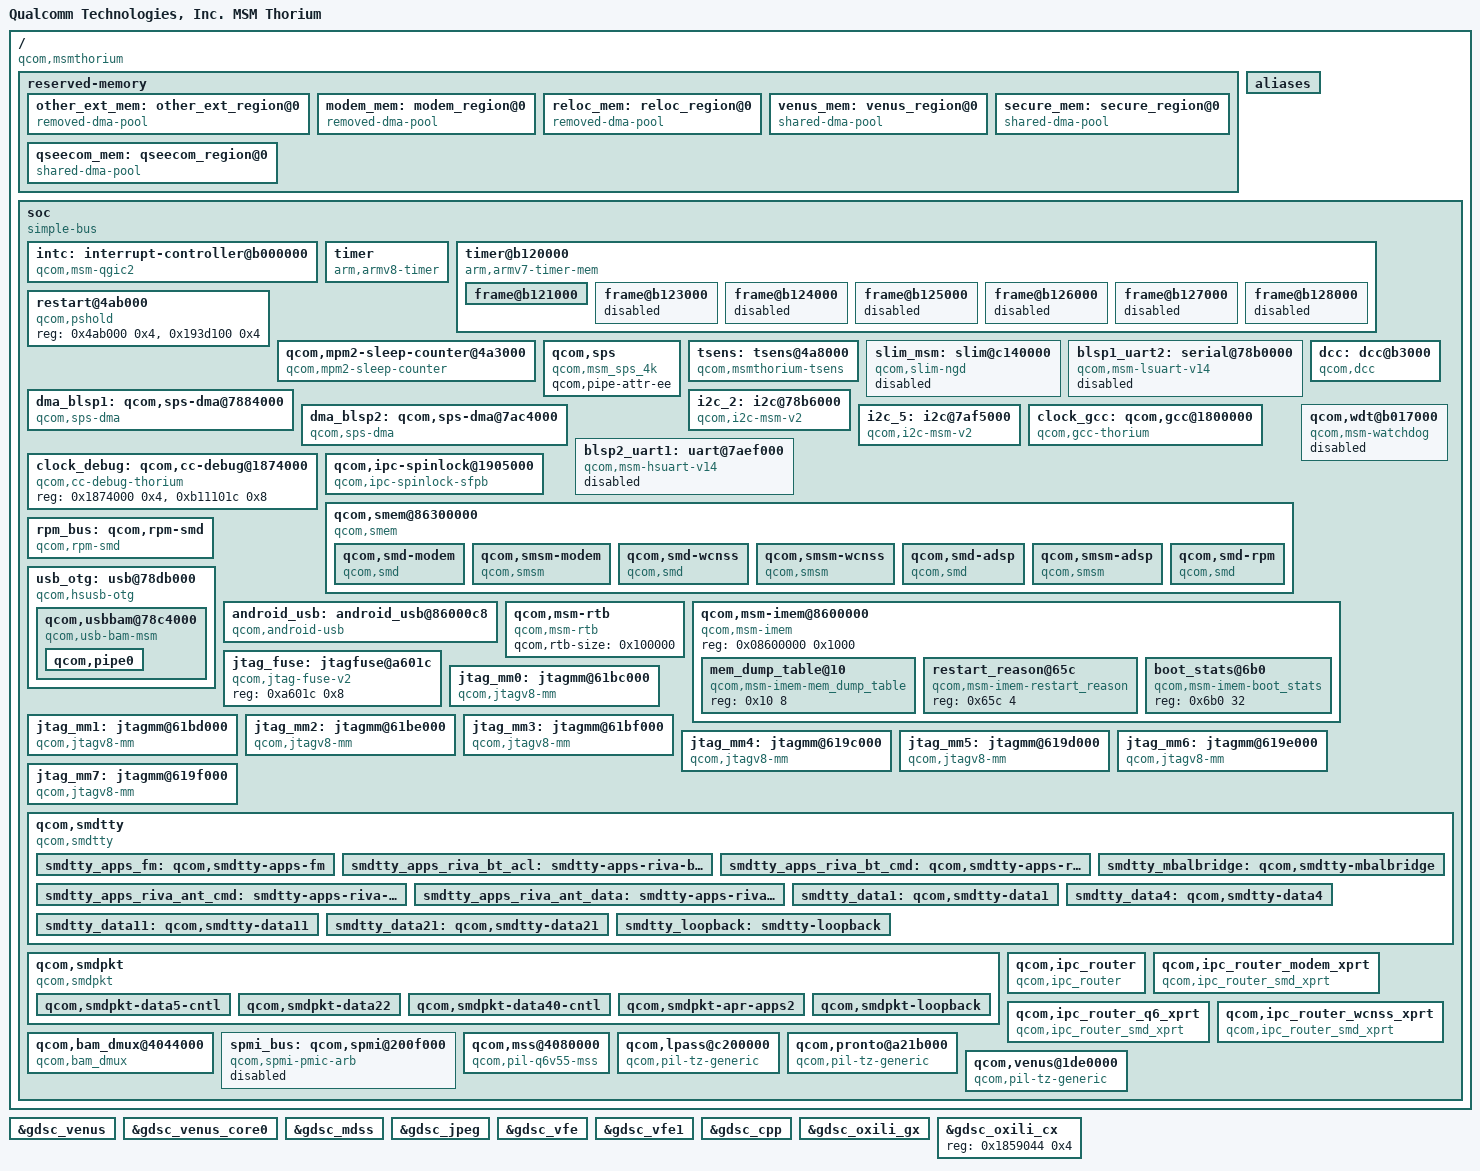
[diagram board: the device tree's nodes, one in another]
/*
 * Copyright (c) 2015, The Linux Foundation. All rights reserved.
 *
 * This program is free software; you can redistribute it and/or modify
 * it under the terms of the GNU General Public License version 2 and
 * only version 2 as published by the Free Software Foundation.
 *
 * This program is distributed in the hope that it will be useful,
 * but WITHOUT ANY WARRANTY; without even the implied warranty of
 * MERCHANTABILITY or FITNESS FOR A PARTICULAR PURPOSE.  See the
 * GNU General Public License for more details.
 */

#include "skeleton64.dtsi"
#include <dt-bindings/clock/msm-clocks-8952.h>
#include <dt-bindings/regulator/qcom,rpm-smd-regulator.h>

/ {
	model = "Qualcomm Technologies, Inc. MSM Thorium";
	compatible = "qcom,msmthorium";
	qcom,msm-id = <294 0x0>;
	interrupt-parent = <&intc>;

	reserved-memory {
		#address-cells = <2>;
		#size-cells = <2>;
		ranges;

		other_ext_mem: other_ext_region@0 {
			compatible = "removed-dma-pool";
			no-map;
			reg = <0x0 0x85e00000 0x0 0xa00000>;
		};

		modem_mem: modem_region@0 {
			compatible = "removed-dma-pool";
			no-map;
			reg = <0x0 0x86800000 0x0 0x5a00000>;
		};

		reloc_mem: reloc_region@0 {
			compatible = "removed-dma-pool";
			no-map;
			reg = <0x0 0x8c200000 0x0 0x1b00000>;
		};

		venus_mem: venus_region@0 {
			compatible = "shared-dma-pool";
			reusable;
			alloc-ranges = <0x0 0x80000000 0x0 0x10000000>;
			alignment = <0 0x400000>;
			size = <0 0x0800000>;
		};

		secure_mem: secure_region@0 {
			compatible = "shared-dma-pool";
			reusable;
			alignment = <0 0x400000>;
			size = <0 0x7000000>;
		};

		qseecom_mem: qseecom_region@0 {
			compatible = "shared-dma-pool";
			reusable;
			alignment = <0 0x400000>;
			size = <0 0x1000000>;
		};
	};

	aliases {
		/* smdtty devices */
		smd1 = &smdtty_apps_fm;
		smd2 = &smdtty_apps_riva_bt_acl;
		smd3 = &smdtty_apps_riva_bt_cmd;
		smd4 = &smdtty_mbalbridge;
		smd5 = &smdtty_apps_riva_ant_cmd;
		smd6 = &smdtty_apps_riva_ant_data;
		smd7 = &smdtty_data1;
		smd8 = &smdtty_data4;
		smd11 = &smdtty_data11;
		smd21 = &smdtty_data21;
		smd36 = &smdtty_loopback;
		i2c2 = &i2c_2;
		i2c5 = &i2c_5;
	};

	soc: soc { };

};

#include "msmthorium-pinctrl.dtsi"
#include "msmthorium-cpu.dtsi"
#include "msmthorium-ion.dtsi"
#include "msm-arm-smmu-thorium.dtsi"
#include "msmthorium-coresight.dtsi"
#include "msmthorium-smp2p.dtsi"

&soc {
	#address-cells = <1>;
	#size-cells = <1>;
	ranges = <0 0 0 0xffffffff>;
	compatible = "simple-bus";

	intc: interrupt-controller@b000000 {
		compatible = "qcom,msm-qgic2";
		interrupt-controller;
		#interrupt-cells = <3>;
		reg = <0x0b000000 0x1000>,
		      <0x0b002000 0x1000>;
	};

	timer {
		compatible = "arm,armv8-timer";
		interrupts = <1 2 0xff08>,
			     <1 3 0xff08>,
			     <1 4 0xff08>,
			     <1 1 0xff08>;
		clock-frequency = <19200000>;
	};

	timer@b120000 {
		#address-cells = <1>;
		#size-cells = <1>;
		ranges;
		compatible = "arm,armv7-timer-mem";
		reg = <0xb120000 0x1000>;
		clock-frequency = <19200000>;

		frame@b121000 {
			frame-number = <0>;
			interrupts = <0 8 0x4>,
				     <0 7 0x4>;
			reg = <0xb121000 0x1000>,
			      <0xb122000 0x1000>;
		};

		frame@b123000 {
			frame-number = <1>;
			interrupts = <0 9 0x4>;
			reg = <0xb123000 0x1000>;
			status = "disabled";
		};

		frame@b124000 {
			frame-number = <2>;
			interrupts = <0 10 0x4>;
			reg = <0xb124000 0x1000>;
			status = "disabled";
		};

		frame@b125000 {
			frame-number = <3>;
			interrupts = <0 11 0x4>;
			reg = <0xb125000 0x1000>;
			status = "disabled";
		};

		frame@b126000 {
			frame-number = <4>;
			interrupts = <0 12 0x4>;
			reg = <0xb126000 0x1000>;
			status = "disabled";
		};

		frame@b127000 {
			frame-number = <5>;
			interrupts = <0 13 0x4>;
			reg = <0xb127000 0x1000>;
			status = "disabled";
		};

		frame@b128000 {
			frame-number = <6>;
			interrupts = <0 14 0x4>;
			reg = <0xb128000 0x1000>;
			status = "disabled";
		};
	};

	restart@4ab000 {
		compatible = "qcom,pshold";
		reg = <0x4ab000 0x4>,
			<0x193d100 0x4>;
		reg-names = "pshold-base", "tcsr-boot-misc-detect";
	};

	qcom,mpm2-sleep-counter@4a3000 {
		compatible = "qcom,mpm2-sleep-counter";
		reg = <0x4a3000 0x1000>;
		clock-frequency = <32768>;
	};

	qcom,sps {
		compatible = "qcom,msm_sps_4k";
		qcom,pipe-attr-ee;
	};

	tsens: tsens@4a8000 {
		compatible = "qcom,msmthorium-tsens";
		reg = <0x4a8000 0x2000>,
		      <0xa4000  0x1000>;
		reg-names = "tsens_physical", "tsens_eeprom_physical";
		interrupts = <0 184 0>;
		interrupt-names = "tsens-upper-lower";
		qcom,sensors = <11>;
		qcom,slope = <3200 3200 3200 3200 3200 3200 3200 3200 3200
								3200 3200>;
		qcom,sensor-id = <0 1 2 3 4 5 6 7 8 9 10>;
	};

	slim_msm: slim@c140000{
		cell-index = <1>;
		compatible = "qcom,slim-ngd";
		reg = <0xc140000 0x2c000>,
		      <0xc104000 0x2a000>;
		reg-names = "slimbus_physical", "slimbus_bam_physical";
		interrupts = <0 163 0>, <0 180 0>;
		interrupt-names = "slimbus_irq", "slimbus_bam_irq";
		qcom,apps-ch-pipes = <0x600000>;
		qcom,ea-pc = <0x230>;
		status = "disabled";
	};

	blsp1_uart2: serial@78b0000 {
		compatible = "qcom,msm-lsuart-v14";
		reg = <0x78b0000 0x200>;
		interrupts = <0 108 0>;
		status = "disabled";
		clocks = <&clock_gcc clk_gcc_blsp1_uart2_apps_clk>,
		<&clock_gcc clk_gcc_blsp1_ahb_clk>;
		clock-names = "core_clk", "iface_clk";
	};

	dma_blsp1: qcom,sps-dma@7884000 { /* BLSP1 */
		#dma-cells = <4>;
		compatible = "qcom,sps-dma";
		reg = <0x7884000 0x1f000>;
		interrupts = <0 238 0>;
		qcom,summing-threshold = <10>;
	};

	dma_blsp2: qcom,sps-dma@7ac4000 { /* BLSP2 */
		#dma-cells = <4>;
		compatible = "qcom,sps-dma";
		reg = <0x7ac4000 0x1f000>;
		interrupts = <0 239 0>;
		qcom,summing-threshold = <10>;
	};

	i2c_2: i2c@78b6000 { /* BLSP1 QUP2 */
		compatible = "qcom,i2c-msm-v2";
		#address-cells = <1>;
		#size-cells = <0>;
		reg-names = "qup_phys_addr";
		reg = <0x78b6000 0x600>;
		interrupt-names = "qup_irq";
		interrupts = <0 96 0>;
		qcom,clk-freq-out = <400000>;
		qcom,clk-freq-in  = <19200000>;
		clock-names = "iface_clk", "core_clk";
		clocks = <&clock_gcc clk_gcc_blsp1_ahb_clk>,
			<&clock_gcc clk_gcc_blsp1_qup2_i2c_apps_clk>;

		pinctrl-names = "i2c_active", "i2c_sleep";
		pinctrl-0 = <&i2c_2_active>;
		pinctrl-1 = <&i2c_2_sleep>;
		qcom,noise-rjct-scl = <0>;
		qcom,noise-rjct-sda = <0>;
		qcom,master-id = <86>;
		dmas = <&dma_blsp1 6 64 0x20000020 0x20>,
			<&dma_blsp1 7 32 0x20000020 0x20>;
		dma-names = "tx", "rx";
	};

	i2c_5: i2c@7af5000 { /* BLSP2 QUP1 */
		compatible = "qcom,i2c-msm-v2";
		#address-cells = <1>;
		#size-cells = <0>;
		reg-names = "qup_phys_addr";
		reg = <0x7af5000 0x600>;
		interrupt-names = "qup_irq";
		interrupts = <0 299 0>;
		qcom,clk-freq-out = <400000>;
		qcom,clk-freq-in  = <19200000>;
		clock-names = "iface_clk", "core_clk";
		clocks = <&clock_gcc clk_gcc_blsp2_ahb_clk>,
			<&clock_gcc clk_gcc_blsp2_qup1_i2c_apps_clk>;

		pinctrl-names = "i2c_active", "i2c_sleep";
		pinctrl-0 = <&i2c_5_active>;
		pinctrl-1 = <&i2c_5_sleep>;
		qcom,noise-rjct-scl = <0>;
		qcom,noise-rjct-sda = <0>;
		qcom,master-id = <84>;
		dmas = <&dma_blsp2 4 64 0x20000020 0x20>,
			<&dma_blsp2 5 32 0x20000020 0x20>;
		dma-names = "tx", "rx";
	};

	clock_gcc: qcom,gcc@1800000 {
		compatible = "qcom,gcc-thorium";
		reg = <0x1800000 0x80000>,
			<0xb116000 0x00040>,
			<0xb016000 0x00040>,
			<0xb1d0000 0x00040>;
		reg-names = "cc_base", "apcs_c0_base",
			"apcs_c1_base", "apcs_cci_base";
		vdd_dig-supply = <&pmthorium_s2_level>;
		vdd_sr2_dig-supply = <&pmthorium_s2_level_ao>;
		vdd_sr2_pll-supply = <&pmthorium_l7_ao>;
		vdd_hf_dig-supply = <&pmthorium_s2_level_ao>;
		vdd_hf_pll-supply = <&pmthorium_l7_ao>;
		#clock-cells = <1>;
	};

	clock_debug: qcom,cc-debug@1874000 {
		compatible = "qcom,cc-debug-thorium";
		reg = <0x1874000 0x4>,
		      <0xb11101c 0x8>;
		reg-names = "cc_base", "meas";
		#clock-cells = <1>;
	};

	blsp2_uart1: uart@7aef000 {
		compatible = "qcom,msm-hsuart-v14";
		reg = <0x7aef000 0x200>,
			<0x7ac4000 0x1f000>;
		reg-names = "core_mem", "bam_mem";
		interrupt-names = "core_irq", "bam_irq", "wakeup_irq";
		#address-cells = <0>;
		interrupt-parent = <&blsp2_uart1>;
		interrupts = <0 1 2>;
		#interrupt-cells = <1>;
		interrupt-map-mask = <0xffffffff>;
		interrupt-map = <0 &intc 0 306 0
				1 &intc 0 239 0
				2 &tlmm 17 0>;

		qcom,inject-rx-on-wakeup;
		qcom,rx-char-to-inject = <0xfd>;

		qcom,bam-tx-ep-pipe-index = <0>;
		qcom,bam-rx-ep-pipe-index = <1>;
		qcom,master-id = <84>;
		clock-names = "core_clk", "iface_clk";
		clocks = <&clock_gcc clk_gcc_blsp2_uart1_apps_clk>,
				<&clock_gcc clk_gcc_blsp2_ahb_clk>;
		pinctrl-names = "sleep", "default";
		pinctrl-0 = <&blsp2_uart1_sleep>;
		pinctrl-1 = <&blsp2_uart1_active>;
		qcom,msm-bus,name = "blsp2_uart1";
		qcom,msm-bus,num-cases = <2>;
		qcom,msm-bus,num-paths = <1>;
		qcom,msm-bus,vectors-KBps =
				<84 512 0 0>,
				<84 512 500 800>;
		status = "disabled";
	};

	dcc: dcc@b3000 {
		compatible = "qcom,dcc";
		reg = <0xb3000 0x1000>,
		      <0xb4000 0x2000>;
		reg-names = "dcc-base", "dcc-ram-base";

		clocks = <&clock_gcc clk_gcc_dcc_clk>;
		clock-names = "dcc_clk";

		qcom,save-reg;
	};

	qcom,ipc-spinlock@1905000 {
		compatible = "qcom,ipc-spinlock-sfpb";
		reg = <0x1905000 0x8000>;
		qcom,num-locks = <8>;
	};

	qcom,smem@86300000 {
		compatible = "qcom,smem";
		reg = <0x86300000 0x100000>,
			<0xb011008 0x4>,
			<0x60000 0x8000>,
			<0x193d000 0x8>;
		reg-names = "smem", "irq-reg-base", "aux-mem1",
				"smem_targ_info_reg";
		qcom,mpu-enabled;

		qcom,smd-modem {
			compatible = "qcom,smd";
			qcom,smd-edge = <0>;
			qcom,smd-irq-offset = <0x0>;
			qcom,smd-irq-bitmask = <0x1000>;
			interrupts = <0 25 1>;
			label = "modem";
		};

		qcom,smsm-modem {
			compatible = "qcom,smsm";
			qcom,smsm-edge = <0>;
			qcom,smsm-irq-offset = <0x0>;
			qcom,smsm-irq-bitmask = <0x2000>;
			interrupts = <0 26 1>;
		};

		qcom,smd-wcnss {
			compatible = "qcom,smd";
			qcom,smd-edge = <6>;
			qcom,smd-irq-offset = <0x0>;
			qcom,smd-irq-bitmask = <0x20000>;
			interrupts = <0 142 1>;
			label = "wcnss";
		};

		qcom,smsm-wcnss {
			compatible = "qcom,smsm";
			qcom,smsm-edge = <6>;
			qcom,smsm-irq-offset = <0x0>;
			qcom,smsm-irq-bitmask = <0x80000>;
			interrupts = <0 144 1>;
		};

		qcom,smd-adsp {
			compatible = "qcom,smd";
			qcom,smd-edge = <1>;
			qcom,smd-irq-offset = <0x0>;
			qcom,smd-irq-bitmask = <0x100>;
			interrupts = <0 289 1>;
			label = "adsp";
		};

		qcom,smsm-adsp {
			compatible = "qcom,smsm";
			qcom,smsm-edge = <1>;
			qcom,smsm-irq-offset = <0x0>;
			qcom,smsm-irq-bitmask = <0x200>;
			interrupts = <0 290 1>;
		};

		qcom,smd-rpm {
			compatible = "qcom,smd";
			qcom,smd-edge = <15>;
			qcom,smd-irq-offset = <0x0>;
			qcom,smd-irq-bitmask = <0x1>;
			interrupts = <0 168 1>;
			label = "rpm";
			qcom,irq-no-suspend;
			qcom,not-loadable;
		};
	};

	rpm_bus: qcom,rpm-smd {
		compatible = "qcom,rpm-smd";
		rpm-channel-name = "rpm_requests";
		rpm-channel-type = <15>; /* SMD_APPS_RPM */
		rpm-standalone; /* TODO: Remove once RPM communication is up */
	};

	usb_otg: usb@78db000 {
		compatible = "qcom,hsusb-otg";
		reg = <0x78db000 0x400>, <0x6c000 0x200>;
		reg-names = "core", "phy_csr";
		#address-cells = <1>;
		#size-cells = <1>;
		ranges;

		interrupts = <0 134 0>,<0 140 0>;
		interrupt-names = "core_irq", "async_irq";

		hsusb_vdd_dig-supply = <&pmthorium_l2>;
		HSUSB_1p8-supply = <&pmthorium_l7>;
		HSUSB_3p3-supply = <&pmthorium_l13>;
		vbus_otg-supply = <&smbcharger_charger_otg>;
		qcom,vdd-voltage-level = <0 1200000 1200000>;

		qcom,hsusb-otg-phy-type = <3>; /* SNPS Femto PHY */
		qcom,hsusb-otg-mode = <3>; /* OTG mode */
		qcom,hsusb-otg-otg-control = <2>; /* PMIC */
		qcom,dp-manual-pullup;
		qcom,hsusb-otg-mpm-dpsehv-int = <49>;
		qcom,hsusb-otg-mpm-dmsehv-int = <58>;
		qcom,phy-dvdd-always-on;
		qcom,boost-sysclk-with-streaming;

		qcom,msm-bus,name = "usb2";
		qcom,msm-bus,num-cases = <3>;
		qcom,msm-bus,num-paths = <1>;
		qcom,msm-bus,vectors-KBps =
				<87 512 0 0>,
				<87 512 80000 0>,
				<87 512 6000  6000>;
		clocks = <&clock_gcc clk_gcc_usb_hs_ahb_clk>,
			 <&clock_gcc clk_gcc_usb_hs_system_clk>,
			 <&clock_gcc clk_gcc_usb2a_phy_sleep_clk>,
			 <&clock_gcc clk_bimc_usb_a_clk>,
			 <&clock_gcc clk_snoc_usb_a_clk>,
			 <&clock_gcc clk_pnoc_usb_a_clk>,
			 <&clock_gcc clk_gcc_qusb2_phy_clk>,
			 <&clock_gcc clk_gcc_usb2_hs_phy_only_clk>,
			 <&clock_gcc clk_gcc_usb_hs_phy_cfg_ahb_clk>,
			 <&clock_gcc clk_xo_otg_clk>;
		clock-names = "iface_clk", "core_clk", "sleep_clk",
				"bimc_clk", "snoc_clk", "pcnoc_clk",
				"phy_reset_clk", "phy_por_clk", "phy_csr_clk",
				"xo";
		qcom,bus-clk-rate = <748800000 200000000 100000000>;
		qcom,max-nominal-sysclk-rate = <133330000>;

		qcom,usbbam@78c4000 {
			compatible = "qcom,usb-bam-msm";
			reg = <0x78c4000 0x17000>;
			interrupt-parent = <&intc>;
			interrupts = <0 135 0>;

			qcom,bam-type = <1>;
			qcom,usb-bam-num-pipes = <4>;
			qcom,usb-bam-fifo-baseaddr = <0x08605000>;
			qcom,ignore-core-reset-ack;
			qcom,disable-clk-gating;
			qcom,usb-bam-max-mbps-highspeed = <400>;
			qcom,reset-bam-on-disconnect;

			qcom,pipe0 {
				label = "hsusb-qdss-in-0";
				qcom,usb-bam-mem-type = <2>;
				qcom,dir = <1>;
				qcom,pipe-num = <0>;
				qcom,peer-bam = <0>;
				qcom,peer-bam-physical-address = <0x6044000>;
				qcom,src-bam-pipe-index = <0>;
				qcom,dst-bam-pipe-index = <0>;
				qcom,data-fifo-offset = <0x0>;
				qcom,data-fifo-size = <0xe00>;
				qcom,descriptor-fifo-offset = <0xe00>;
				qcom,descriptor-fifo-size = <0x200>;
			};
		};
	};

	android_usb: android_usb@86000c8 {
		compatible = "qcom,android-usb";
		reg = <0x086000c8 0xc8>;
		qcom,pm-qos-latency = <2 1001 12701>;
	};

	qcom,wdt@b017000 {
		compatible = "qcom,msm-watchdog";
		reg = <0xb017000 0x1000>;
		reg-names = "wdt-base";
		interrupts = <0 3 0>, <0 4 0>;
		qcom,bark-time = <11000>;
		qcom,pet-time = <10000>;
		qcom,ipi-ping;
		qcom,wakeup-enable;
		status = "disabled";
	};

	qcom,msm-rtb {
		compatible = "qcom,msm-rtb";
		qcom,rtb-size = <0x100000>; /* 1M EBI1 buffer */
	};

	qcom,msm-imem@8600000 {
		compatible = "qcom,msm-imem";
		reg = <0x08600000 0x1000>; /* Address and size of IMEM */
		ranges = <0x0 0x08600000 0x1000>;
		#address-cells = <1>;
		#size-cells = <1>;

		mem_dump_table@10 {
			compatible = "qcom,msm-imem-mem_dump_table";
			reg = <0x10 8>;
		};

		restart_reason@65c {
			compatible = "qcom,msm-imem-restart_reason";
			reg = <0x65c 4>;
		};

		boot_stats@6b0 {
			compatible = "qcom,msm-imem-boot_stats";
			reg = <0x6b0 32>;
		};
	};

	jtag_fuse: jtagfuse@a601c {
		compatible = "qcom,jtag-fuse-v2";
		reg = <0xa601c 0x8>;
		reg-names = "fuse-base";
	};

	jtag_mm0: jtagmm@61bc000 {
		compatible = "qcom,jtagv8-mm";
		reg = <0x61bc000 0x1000>,
		      <0x61b0000 0x1000>;
		reg-names = "etm-base", "debug-base";

		qcom,coresight-jtagmm-cpu = <&CPU4>;

		clocks = <&clock_gcc clk_qdss_clk>,
			 <&clock_gcc clk_qdss_a_clk>;
		clock-names = "core_clk", "core_a_clk";
	};

	jtag_mm1: jtagmm@61bd000 {
		compatible = "qcom,jtagv8-mm";
		reg = <0x61bd000 0x1000>,
		      <0x61b2000 0x1000>;
		reg-names = "etm-base", "debug-base";

		qcom,coresight-jtagmm-cpu = <&CPU5>;

		clocks = <&clock_gcc clk_qdss_clk>,
			 <&clock_gcc clk_qdss_a_clk>;
		clock-names = "core_clk", "core_a_clk";
	};

	jtag_mm2: jtagmm@61be000 {
		compatible = "qcom,jtagv8-mm";
		reg = <0x61be000 0x1000>,
		      <0x61b4000 0x1000>;
		reg-names = "etm-base", "debug-base";

		qcom,coresight-jtagmm-cpu = <&CPU6>;

		clocks = <&clock_gcc clk_qdss_clk>,
			 <&clock_gcc clk_qdss_a_clk>;
		clock-names = "core_clk", "core_a_clk";
	};

	jtag_mm3: jtagmm@61bf000 {
		compatible = "qcom,jtagv8-mm";
		reg = <0x61bf000 0x1000>,
		      <0x61b6000 0x1000>;
		reg-names = "etm-base", "debug-base";

		qcom,coresight-jtagmm-cpu = <&CPU7>;

		clocks = <&clock_gcc clk_qdss_clk>,
			 <&clock_gcc clk_qdss_a_clk>;
		clock-names = "core_clk", "core_a_clk";
	};

	jtag_mm4: jtagmm@619c000 {
		compatible = "qcom,jtagv8-mm";
		reg = <0x619c000 0x1000>,
		      <0x6190000 0x1000>;
		reg-names = "etm-base", "debug-base";

		qcom,coresight-jtagmm-cpu = <&CPU0>;

		clocks = <&clock_gcc clk_qdss_clk>,
			 <&clock_gcc clk_qdss_a_clk>;
		clock-names = "core_clk", "core_a_clk";
	};

	jtag_mm5: jtagmm@619d000 {
		compatible = "qcom,jtagv8-mm";
		reg = <0x619d000 0x1000>,
		      <0x6192000 0x1000>;
		reg-names = "etm-base", "debug-base";

		qcom,coresight-jtagmm-cpu = <&CPU1>;

		clocks = <&clock_gcc clk_qdss_clk>,
			 <&clock_gcc clk_qdss_a_clk>;
		clock-names = "core_clk", "core_a_clk";
	};

	jtag_mm6: jtagmm@619e000 {
		compatible = "qcom,jtagv8-mm";
		reg = <0x619e000 0x1000>,
		      <0x6194000 0x1000>;
		reg-names = "etm-base", "debug-base";

		qcom,coresight-jtagmm-cpu = <&CPU2>;

		clocks = <&clock_gcc clk_qdss_clk>,
			 <&clock_gcc clk_qdss_a_clk>;
		clock-names = "core_clk", "core_a_clk";
	};

	jtag_mm7: jtagmm@619f000 {
		compatible = "qcom,jtagv8-mm";
		reg = <0x619f000 0x1000>,
		      <0x6196000 0x1000>;
		reg-names = "etm-base", "debug-base";

		qcom,coresight-jtagmm-cpu = <&CPU3>;

		clocks = <&clock_gcc clk_qdss_clk>,
			 <&clock_gcc clk_qdss_a_clk>;
		clock-names = "core_clk", "core_a_clk";
	};

	qcom,smdtty {
		compatible = "qcom,smdtty";

		smdtty_apps_fm: qcom,smdtty-apps-fm {
			qcom,smdtty-remote = "wcnss";
			qcom,smdtty-port-name = "APPS_FM";
		};

		smdtty_apps_riva_bt_acl: smdtty-apps-riva-bt-acl {
			qcom,smdtty-remote = "wcnss";
			qcom,smdtty-port-name = "APPS_RIVA_BT_ACL";
		};

		smdtty_apps_riva_bt_cmd: qcom,smdtty-apps-riva-bt-cmd {
			qcom,smdtty-remote = "wcnss";
			qcom,smdtty-port-name = "APPS_RIVA_BT_CMD";
		};

		smdtty_mbalbridge: qcom,smdtty-mbalbridge {
			qcom,smdtty-remote = "modem";
			qcom,smdtty-port-name = "MBALBRIDGE";
		};

		smdtty_apps_riva_ant_cmd: smdtty-apps-riva-ant-cmd {
			qcom,smdtty-remote = "wcnss";
			qcom,smdtty-port-name = "APPS_RIVA_ANT_CMD";
		};

		smdtty_apps_riva_ant_data: smdtty-apps-riva-ant-data {
			qcom,smdtty-remote = "wcnss";
			qcom,smdtty-port-name = "APPS_RIVA_ANT_DATA";
		};

		smdtty_data1: qcom,smdtty-data1 {
			qcom,smdtty-remote = "modem";
			qcom,smdtty-port-name = "DATA1";
		};

		smdtty_data4: qcom,smdtty-data4 {
			qcom,smdtty-remote = "modem";
			qcom,smdtty-port-name = "DATA4";
		};

		smdtty_data11: qcom,smdtty-data11 {
			qcom,smdtty-remote = "modem";
			qcom,smdtty-port-name = "DATA11";
		};

		smdtty_data21: qcom,smdtty-data21 {
			qcom,smdtty-remote = "modem";
			qcom,smdtty-port-name = "DATA21";
		};

		smdtty_loopback: smdtty-loopback {
			qcom,smdtty-remote = "modem";
			qcom,smdtty-port-name = "LOOPBACK";
			qcom,smdtty-dev-name = "LOOPBACK_TTY";
		};
	};

	qcom,smdpkt {
		compatible = "qcom,smdpkt";

		qcom,smdpkt-data5-cntl {
			qcom,smdpkt-remote = "modem";
			qcom,smdpkt-port-name = "DATA5_CNTL";
			qcom,smdpkt-dev-name = "smdcntl0";
		};

		qcom,smdpkt-data22 {
			qcom,smdpkt-remote = "modem";
			qcom,smdpkt-port-name = "DATA22";
			qcom,smdpkt-dev-name = "smd22";
		};

		qcom,smdpkt-data40-cntl {
			qcom,smdpkt-remote = "modem";
			qcom,smdpkt-port-name = "DATA40_CNTL";
			qcom,smdpkt-dev-name = "smdcntl8";
		};

		qcom,smdpkt-apr-apps2 {
			qcom,smdpkt-remote = "adsp";
			qcom,smdpkt-port-name = "apr_apps2";
			qcom,smdpkt-dev-name = "apr_apps2";
		};

		qcom,smdpkt-loopback {
			qcom,smdpkt-remote = "modem";
			qcom,smdpkt-port-name = "LOOPBACK";
			qcom,smdpkt-dev-name = "smd_pkt_loopback";
		};
	};

	qcom,ipc_router {
		compatible = "qcom,ipc_router";
		qcom,node-id = <1>;
		qcom,default-peripheral = "modem";
	};

	qcom,ipc_router_modem_xprt {
		compatible = "qcom,ipc_router_smd_xprt";
		qcom,ch-name = "IPCRTR";
		qcom,xprt-remote = "modem";
		qcom,xprt-linkid = <1>;
		qcom,xprt-version = <1>;
		qcom,fragmented-data;
	};

	qcom,ipc_router_q6_xprt {
		compatible = "qcom,ipc_router_smd_xprt";
		qcom,ch-name = "IPCRTR";
		qcom,xprt-remote = "adsp";
		qcom,xprt-linkid = <1>;
		qcom,xprt-version = <1>;
		qcom,fragmented-data;
	};

	qcom,ipc_router_wcnss_xprt {
		compatible = "qcom,ipc_router_smd_xprt";
		qcom,ch-name = "IPCRTR";
		qcom,xprt-remote = "wcnss";
		qcom,xprt-linkid = <1>;
		qcom,xprt-version = <1>;
		qcom,fragmented-data;
	};

	qcom,bam_dmux@4044000 {
		compatible = "qcom,bam_dmux";
		reg = <0x4044000 0x19000>;
		interrupts = <0 29 1>;
		qcom,rx-ring-size = <32>;
		qcom,max-rx-mtu = <4096>;
		qcom,fast-shutdown;
	};

	spmi_bus: qcom,spmi@200f000 {
		compatible = "qcom,spmi-pmic-arb";
		reg = <0x200f000 0x1000>,
			<0x2400000 0x800000>,
			<0x2c00000 0x800000>,
			<0x3800000 0x200000>,
			<0x200a000 0x2100>;
		reg-names = "core", "chnls", "obsrvr", "intr", "cnfg";
		interrupts = <0 190 0>;
		qcom,pmic-arb-channel = <0>;
		qcom,pmic-arb-max-peripherals = <256>;
		qcom,pmic-arb-max-periph-interrupts = <256>;
		qcom,pmic-arb-ee = <0>;
		#interrupt-cells = <3>;
		interrupt-controller;
		#address-cells = <1>;
		#size-cells = <0>;
		cell-index = <0>;
		qcom,not-wakeup;
		status = "disabled";
	};

	qcom,mss@4080000 {
		compatible = "qcom,pil-q6v55-mss";
		reg = <0x04080000 0x100>,
		      <0x0194f000 0x010>,
		      <0x01950000 0x008>,
		      <0x01951000 0x008>,
		      <0x04020000 0x040>,
		      <0x01871000 0x004>;
		reg-names = "qdsp6_base", "halt_q6", "halt_modem", "halt_nc",
				 "rmb_base", "restart_reg";

		interrupts = <0 24 1>;
		vdd_mss-supply = <&pmthorium_s1>;
		vdd_cx-supply = <&pmthorium_s2_level>;
		vdd_cx-voltage = <RPM_SMD_REGULATOR_LEVEL_TURBO>;
		vdd_mx-supply = <&pmthorium_l3_level_ao>;
		vdd_mx-uV = <RPM_SMD_REGULATOR_LEVEL_TURBO>;
		vdd_pll-supply = <&pmthorium_l7>;
		qcom,vdd_pll = <1800000>;

		clocks = <&clock_gcc clk_xo_pil_mss_clk>,
			 <&clock_gcc clk_gcc_mss_cfg_ahb_clk>,
			 <&clock_gcc clk_gcc_mss_q6_bimc_axi_clk>,
			 <&clock_gcc clk_gcc_boot_rom_ahb_clk>;
		clock-names = "xo", "iface_clk", "bus_clk", "mem_clk";
		qcom,proxy-clock-names = "xo";
		qcom,active-clock-names = "iface_clk", "bus_clk", "mem_clk";

		qcom,firmware-name = "modem";
		qcom,pil-self-auth;
		qcom,sysmon-id = <0>;
		qcom,ssctl-instance-id = <0x12>;
		qcom,qdsp6v56-1-8-inrush-current;

		/* GPIO inputs from mss */
		qcom,gpio-err-fatal = <&smp2pgpio_ssr_smp2p_1_in 0 0>;
		qcom,gpio-err-ready = <&smp2pgpio_ssr_smp2p_1_in 1 0>;
		qcom,gpio-proxy-unvote = <&smp2pgpio_ssr_smp2p_1_in 2 0>;
		qcom,gpio-stop-ack = <&smp2pgpio_ssr_smp2p_1_in 3 0>;
		qcom,gpio-shutdown-ack = <&smp2pgpio_ssr_smp2p_1_in 7 0>;

		/* GPIO output to mss */
		qcom,gpio-force-stop = <&smp2pgpio_ssr_smp2p_1_out 0 0>;
		memory-region = <&modem_mem>;
	};

	qcom,lpass@c200000 {
		compatible = "qcom,pil-tz-generic";
		reg = <0xc200000 0x00100>;
		interrupts = <0 293 1>;

		vdd_cx-supply = <&pmthorium_s2_level>;
		qcom,proxy-reg-names = "vdd_cx";
		qcom,vdd_cx-uV-uA = <RPM_SMD_REGULATOR_LEVEL_TURBO 100000>;

		clocks = <&clock_gcc clk_xo_pil_lpass_clk>,
			 <&clock_gcc clk_gcc_crypto_clk>,
			 <&clock_gcc clk_gcc_crypto_ahb_clk>,
			 <&clock_gcc clk_gcc_crypto_axi_clk>,
			 <&clock_gcc clk_crypto_clk_src>;
		clock-names = "xo", "scm_core_clk", "scm_iface_clk",
				"scm_bus_clk", "scm_core_clk_src";
		qcom,proxy-clock-names = "xo", "scm_core_clk", "scm_iface_clk",
				 "scm_bus_clk", "scm_core_clk_src";
		qcom,scm_core_clk_src-freq = <80000000>;

		qcom,pas-id = <1>;
		qcom,proxy-timeout-ms = <10000>;
		qcom,smem-id = <423>;
		qcom,sysmon-id = <1>;
		qcom,ssctl-instance-id = <0x14>;
		qcom,firmware-name = "adsp";

		/* GPIO inputs from lpass */
		qcom,gpio-err-fatal = <&smp2pgpio_ssr_smp2p_2_in 0 0>;
		qcom,gpio-proxy-unvote = <&smp2pgpio_ssr_smp2p_2_in 2 0>;
		qcom,gpio-err-ready = <&smp2pgpio_ssr_smp2p_2_in 1 0>;
		qcom,gpio-stop-ack = <&smp2pgpio_ssr_smp2p_2_in 3 0>;

		/* GPIO output to lpass */
		qcom,gpio-force-stop = <&smp2pgpio_ssr_smp2p_2_out 0 0>;

		memory-region = <&reloc_mem>;
	};

	qcom,pronto@a21b000 {
		compatible = "qcom,pil-tz-generic";
		reg = <0x0a21b000 0x3000>;
		interrupts = <0 149 1>;

		vdd_pronto_pll-supply = <&pmthorium_l7>;
		proxy-reg-names = "vdd_pronto_pll";
		vdd_pronto_pll-uV-uA = <1800000 18000>;
		clocks = <&clock_gcc clk_xo_pil_pronto_clk>,
			 <&clock_gcc clk_gcc_crypto_clk>,
			 <&clock_gcc clk_gcc_crypto_ahb_clk>,
			 <&clock_gcc clk_gcc_crypto_axi_clk>,
			 <&clock_gcc clk_crypto_clk_src>;

		clock-names = "xo", "scm_core_clk", "scm_iface_clk",
				"scm_bus_clk", "scm_core_clk_src";
		qcom,proxy-clock-names = "xo", "scm_core_clk", "scm_iface_clk",
				 "scm_bus_clk", "scm_core_clk_src";
		qcom,scm_core_clk_src = <80000000>;

		qcom,pas-id = <6>;
		qcom,proxy-timeout-ms = <10000>;
		qcom,smem-id = <422>;
		qcom,sysmon-id = <6>;
		qcom,ssctl-instance-id = <0x13>;
		qcom,firmware-name = "wcnss";

		/* GPIO inputs from wcnss */
		qcom,gpio-err-fatal = <&smp2pgpio_ssr_smp2p_4_in 0 0>;
		qcom,gpio-err-ready = <&smp2pgpio_ssr_smp2p_4_in 1 0>;
		qcom,gpio-proxy-unvote = <&smp2pgpio_ssr_smp2p_4_in 2 0>;
		qcom,gpio-stop-ack = <&smp2pgpio_ssr_smp2p_4_in 3 0>;

		/* GPIO output to wcnss */
		qcom,gpio-force-stop = <&smp2pgpio_ssr_smp2p_4_out 0 0>;
		memory-region = <&reloc_mem>;
	};

	qcom,venus@1de0000 {
		compatible = "qcom,pil-tz-generic";
		reg = <0x1de0000 0x4000>;

		vdd-supply = <&gdsc_venus>;
		qcom,proxy-reg-names = "vdd";

		clocks = <&clock_gcc clk_gcc_venus0_vcodec0_clk>,
			 <&clock_gcc clk_gcc_venus0_ahb_clk>,
			 <&clock_gcc clk_gcc_venus0_axi_clk>,
			 <&clock_gcc clk_gcc_crypto_clk>,
			 <&clock_gcc clk_gcc_crypto_ahb_clk>,
			 <&clock_gcc clk_gcc_crypto_axi_clk>,
			 <&clock_gcc clk_crypto_clk_src>;

		clock-names = "core_clk", "iface_clk", "bus_clk",
				"scm_core_clk", "scm_iface_clk",
				"scm_bus_clk", "scm_core_clk_src";

		qcom,proxy-clock-names = "core_clk", "iface_clk",
					 "bus_clk", "scm_core_clk",
					 "scm_iface_clk", "scm_bus_clk",
					 "scm_core_clk_src";
		qcom,scm_core_clk_src-freq = <80000000>;

		qcom,msm-bus,name = "pil-venus";
		qcom,msm-bus,num-cases = <2>;
		qcom,msm-bus,num-paths = <1>;
		qcom,msm-bus,vectors-KBps =
				<63 512 0 0>,
				<63 512 0 304000>;

		qcom,pas-id = <9>;
		qcom,proxy-timeout-ms = <100>;
		qcom,firmware-name = "venus";
		memory-region = <&venus_mem>;
	};

};

#include "msm-pmthorium-rpm-regulator.dtsi"
#include "msmthorium-regulator.dtsi"
#include "msm-pmthorium.dtsi"
#include "msm-pmithorium.dtsi"
#include "msm-gdsc-8916.dtsi"

&gdsc_venus {
	clock-names = "bus_clk", "core_clk";
	clocks = <&clock_gcc clk_gcc_venus0_axi_clk>,
		 <&clock_gcc clk_gcc_venus0_vcodec0_clk>;
	status = "okay";
};

&gdsc_venus_core0 {
	qcom,support-hw-trigger;
	clock-names ="core0_clk";
	clocks = <&clock_gcc clk_gcc_venus0_core0_vcodec0_clk>;
	status = "okay";
};

&gdsc_mdss {
	clock-names = "core_clk", "bus_clk";
	clocks = <&clock_gcc clk_gcc_mdss_mdp_clk>,
		 <&clock_gcc clk_gcc_mdss_axi_clk>;
	status = "okay";
};

&gdsc_jpeg {
	clock-names = "core_clk", "bus_clk";
	clocks = <&clock_gcc clk_gcc_camss_jpeg0_clk>,
		 <&clock_gcc clk_gcc_camss_jpeg_axi_clk>;
	status = "okay";
};

&gdsc_vfe {
	clock-names = "core_clk", "bus_clk", "micro_clk",
			"csi_clk";
	clocks = <&clock_gcc clk_gcc_camss_vfe0_clk>,
		 <&clock_gcc clk_gcc_camss_vfe_axi_clk>,
		 <&clock_gcc clk_gcc_camss_micro_ahb_clk>,
		 <&clock_gcc clk_gcc_camss_csi_vfe0_clk>;
	status = "okay";
};

&gdsc_vfe1 {
	clock-names = "core_clk", "bus_clk", "micro_clk",
			"csi_clk";
	clocks = <&clock_gcc clk_gcc_camss_vfe1_clk>,
		 <&clock_gcc clk_gcc_camss_vfe1_axi_clk>,
		 <&clock_gcc clk_gcc_camss_micro_ahb_clk>,
		 <&clock_gcc clk_gcc_camss_csi_vfe1_clk>;
	status = "okay";
};

&gdsc_cpp {
	clock-names = "core_clk", "bus_clk";
	clocks = <&clock_gcc clk_gcc_camss_cpp_clk>,
		 <&clock_gcc clk_gcc_camss_cpp_axi_clk>;
	status = "okay";
};

&gdsc_oxili_gx {
	clock-names = "core_root_clk", "gmem_clk";
	clocks =<&clock_gcc clk_gfx3d_clk_src>,
		<&clock_gcc clk_gcc_oxili_gmem_clk>;
	qcom,enable-root-clk;
	qcom,clk-dis-wait-val = <0x5>;
	status = "okay";
};

&gdsc_oxili_cx {
	reg = <0x1859044 0x4>;
	status = "okay";
};
